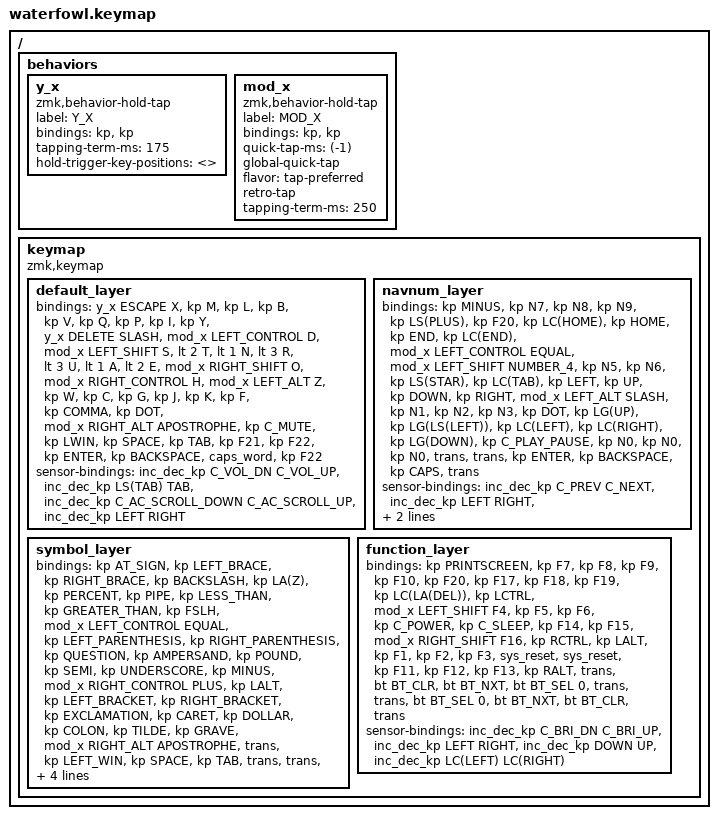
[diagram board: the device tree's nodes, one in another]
#include <behaviors.dtsi>
#include <dt-bindings/zmk/bt.h>
#include <dt-bindings/zmk/keys.h>

/ {
    behaviors {
        y_x: y_x {
            compatible = "zmk,behavior-hold-tap";
            label = "Y_X";
            bindings =
                <&kp>,
                <&kp>;

            #binding-cells = <2>;
            tapping-term-ms = <175>;
            hold-trigger-key-positions = <>;
        };
        mod_x: mod_x {
            compatible = "zmk,behavior-hold-tap";
            label = "MOD_X";
            bindings =
                <&kp>,
                <&kp>;

            #binding-cells = <2>;
            quick-tap-ms = <(-1)>;
            global-quick-tap;
            flavor = "tap-preferred";
            retro-tap;
            tapping-term-ms = <250>;
        };
    };

    keymap {
        compatible = "zmk,keymap";

        default_layer {
            /* XMLBV
 *
 * ,----------------------------------.                      ,----------------------------------.
 * |   X  |   M  |   L  |   B  |   V  |                      |   Q  |   P  |   I  |   Y  |   /  |
 * |------+------+------+------+------|                      |------+------+------+------+------|
 * |   D  |   S  |   T  |   N  |   R  |                      |   U  |   A  |   E  |   O  |   H  |
 * |------+------+------+------+------|  ,-----.    ,-----.  |------+------+------+------+------|
 * |   Z  |   W  |   C  |   G  |   J  |  | F21 |    | F22 |  |   K  |   F  |   ,  |   .  |   '  |
 * `----------------------------------'  `-----'    `-----'  `----------------------------------'
 *          ,-----.   ,--------------------.            ,--------------------.   ,-----. 
 *          | PLY |   | WIN | TAB |  SPACE |            | BS  | ENTER | CAPS |   | F22 |	
 *          `-----'   `--------------------'            `--------------------'   `-----'
 */

            bindings = <
&y_x ESCAPE X  &kp M  &kp L  &kp B  &kp V  &kp Q  &kp P  &kp I  &kp Y  &y_x DELETE SLASH  &mod_x LEFT_CONTROL D  &mod_x LEFT_SHIFT S  &lt 2 T  &lt 1 N  &lt 3 R  &lt 3 U  &lt 1 A  &lt 2 E  &mod_x RIGHT_SHIFT O  &mod_x RIGHT_CONTROL H  &mod_x LEFT_ALT Z  &kp W  &kp C  &kp G  &kp J  &kp K  &kp F  &kp COMMA  &kp DOT  &mod_x RIGHT_ALT APOSTROPHE  &kp C_MUTE  &kp LWIN  &kp SPACE  &kp TAB  &kp F21  &kp F22  &kp ENTER  &kp BACKSPACE  &caps_word  &kp F22
            >;

            sensor-bindings = <
				&inc_dec_kp C_VOL_DN C_VOL_UP
				&inc_dec_kp LS(TAB) TAB
				&inc_dec_kp C_AC_SCROLL_DOWN C_AC_SCROLL_UP
				&inc_dec_kp LEFT RIGHT
            >;
        };

        navnum_layer {
            /* NAVNUM
 *
 * ,----------------------------------.                      ,----------------------------------.
 * |      | PgUp |  UP  | PgDn |      |                      |   /  |   7  |   8  |   9  |   -  |
 * |------+------+------+------+------|                      |------+------+------+------+------|
 * | Home | Left | Down | Right| End  |                      |   =  |   4  |   5  |   6  |   +  |
 * |------+------+------+------+------|  ,-----.    ,-----.  |------+------+------+------+------|
 * |      |      |  INS |      |      |  |  2  |    |  3  |  |   0  |   1  |   2  |   3  |   *  |
 * `----------------------------------'  `-----'    `-----'  `----------------------------------'
 *          ,-----.   ,--------------------.            ,--------------------.   ,-----. 
 *          |  1  |   | DEL | SPACE | MO(3)|            |  ESC  | BS | ENTER |   |  4  |
 *          `-----'   `--------------------'            `--------------------'   `-----'
 */

            bindings = <
&kp MINUS  &kp N7  &kp N8  &kp N9  &kp LS(PLUS)  &kp F20  &kp LC(HOME)  &kp HOME  &kp END  &kp LC(END)  &mod_x LEFT_CONTROL EQUAL  &mod_x LEFT_SHIFT NUMBER_4  &kp N5  &kp N6  &kp LS(STAR)  &kp LC(TAB)  &kp LEFT  &kp UP  &kp DOWN  &kp RIGHT  &mod_x LEFT_ALT SLASH  &kp N1  &kp N2  &kp N3  &kp DOT  &kp LG(UP)  &kp LG(LS(LEFT))  &kp LC(LEFT)  &kp LC(RIGHT)  &kp LG(DOWN)  &kp C_PLAY_PAUSE  &kp N0  &kp N0  &kp N0  &trans  &trans  &kp ENTER  &kp BACKSPACE  &kp CAPS  &trans
            >;

            sensor-bindings = <
				&inc_dec_kp C_PREV C_NEXT
				&inc_dec_kp LEFT RIGHT
				&inc_dec_kp LC(C_AC_SCROLL_DOWN) LC(C_AC_SCROLL_UP)
				&inc_dec_kp LC(LEFT) LC(RIGHT)
            >;
        };

        symbol_layer {
            /* SYM
 *
 * ,----------------------------------.                      ,----------------------------------.
 * |   %  |   @  |   [  |   ]  |   \  |                      |      |      |   ^  |      |      |
 * |------+------+------+------+------|                      |------+------+------+------+------|
 * |   #  |   !  |   (  |   )  |   |  |                      |   _  |   '  |   "  |   ~  |   `  |
 * |------+------+------+------+------|  ,-----.    ,-----.  |------+------+------+------+------|
 * |   $  |      |   {  |   }  |   &  |  |  2  |    |  3  |  |      |      |      |      |      |
 * `----------------------------------'  `-----'    `-----'  `----------------------------------'
 *          ,-----.   ,--------------------.            ,--------------------.   ,-----. 
 *          |  1  |   | DEL | SPACE | TAB  |            |  ESC  | BS | ENTER |   |  4  |
 *          `-----'   `--------------------'            `--------------------'   `-----'
 */

            bindings = <
&kp AT_SIGN  &kp LEFT_BRACE  &kp RIGHT_BRACE  &kp BACKSLASH  &kp LA(Z)  &kp PERCENT  &kp PIPE  &kp LESS_THAN  &kp GREATER_THAN  &kp FSLH  &mod_x LEFT_CONTROL EQUAL  &kp LEFT_PARENTHESIS  &kp RIGHT_PARENTHESIS  &kp QUESTION  &kp AMPERSAND  &kp POUND  &kp SEMI  &kp UNDERSCORE  &kp MINUS  &mod_x RIGHT_CONTROL PLUS  &kp LALT  &kp LEFT_BRACKET  &kp RIGHT_BRACKET  &kp EXCLAMATION  &kp CARET  &kp DOLLAR  &kp COLON  &kp TILDE  &kp GRAVE  &mod_x RIGHT_ALT APOSTROPHE  &trans  &kp LEFT_WIN  &kp SPACE  &kp TAB  &trans  &trans  &trans  &trans  &kp CAPS  &trans
            >;

            sensor-bindings = <
				&inc_dec_kp C_RW C_FF
				&inc_dec_kp LEFT RIGHT
				&inc_dec_kp DOWN UP
				&inc_dec_kp LC(LEFT) LC(RIGHT)
            >;
        };

        function_layer {
            /* FUNC
 *
 * ,----------------------------------.                      ,----------------------------------.
 * |      |      | BTCLR|      | Reset|                      | Reset|  F7  |  F8  |  F9  |  F11 |
 * |------+------+------+------+------|                      |------+------+------+------+------|
 * |  BT0 |  BT1 |  BT2 |  BT3 |  BT4 |                      |      |  F4  |  F5  |  F6  |  F12 |
 * |------+------+------+------+------|  ,-----.    ,-----.  |------+------+------+------+------|
 * |      |      |      |      |      |  |  2  |    |  3  |  |  F10 |  F1  |  F2  |  F3  |  F13 |
 * `----------------------------------'  `-----'    `-----'  `----------------------------------'
 *          ,-----.   ,--------------------.            ,--------------------.   ,-----. 
 *          |  1  |   | DEL | SPACE | TAB  |            |  ESC  | BS | ENTER |   |  4  |
 *          `-----'   `--------------------'            `--------------------'   `-----'
 */

            bindings = <
&kp PRINTSCREEN  &kp F7  &kp F8  &kp F9  &kp F10  &kp F20  &kp F17  &kp F18  &kp F19  &kp LC(LA(DEL))  &kp LCTRL  &mod_x LEFT_SHIFT F4  &kp F5  &kp F6  &kp C_POWER  &kp C_SLEEP  &kp F14  &kp F15  &mod_x RIGHT_SHIFT F16  &kp RCTRL  &kp LALT  &kp F1  &kp F2  &kp F3  &sys_reset  &sys_reset  &kp F11  &kp F12  &kp F13  &kp RALT  &trans  &bt BT_CLR  &bt BT_NXT  &bt BT_SEL 0  &trans  &trans  &bt BT_SEL 0  &bt BT_NXT  &bt BT_CLR  &trans
            >;

            sensor-bindings = <
				&inc_dec_kp C_BRI_DN C_BRI_UP
				&inc_dec_kp LEFT RIGHT
				&inc_dec_kp DOWN UP
				&inc_dec_kp LC(LEFT) LC(RIGHT)
            >;
        };
    };
};
